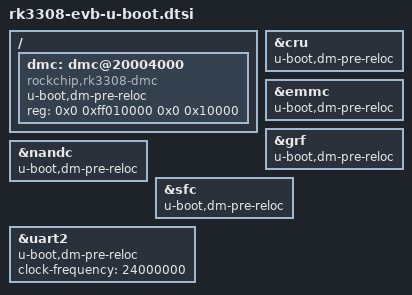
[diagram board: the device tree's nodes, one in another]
/*
 * (C) Copyright 2018 Rockchip Electronics Co., Ltd
 *
 * SPDX-License-Identifier:     GPL-2.0+
 */

/ {
	dmc: dmc@20004000 {
		u-boot,dm-pre-reloc;
		compatible = "rockchip,rk3308-dmc";
		reg = <0x0 0xff010000 0x0 0x10000>;
	};
};

&cru {
        u-boot,dm-pre-reloc;
};

&emmc {
	u-boot,dm-pre-reloc;
};

&grf {
	u-boot,dm-pre-reloc;
};

&nandc {
	u-boot,dm-pre-reloc;
	status = "okay";
};

&sfc {
	u-boot,dm-pre-reloc;
	status = "okay";
};

&uart2 {
	u-boot,dm-pre-reloc;
	clock-frequency = <24000000>;
	status = "okay";
};
